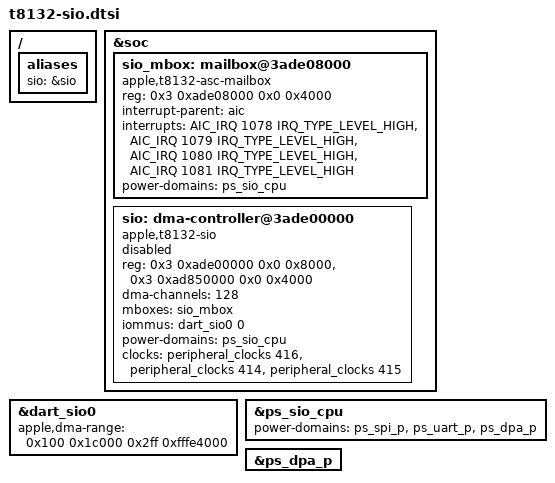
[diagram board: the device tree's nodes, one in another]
// SPDX-License-Identifier: GPL-2.0+ OR MIT
/*
 * T8132 SIO resources. iBoot preloads the SIO firmware; the boot loader
 * reserves it, publishes the boot tables (T6041 layout) and enables the SIO
 * node, which it finds by the alias. Without such a loader the SIO stays
 * disabled and nothing else changes.
 */

/ {
	aliases {
		sio = &sio;
	};
};

&soc {
	sio_mbox: mailbox@3ade08000 {
		compatible = "apple,t8132-asc-mailbox", "apple,asc-mailbox-v4";
		reg = <0x3 0xade08000 0x0 0x4000>;
		interrupt-parent = <&aic>;
		interrupts = <AIC_IRQ 1078 IRQ_TYPE_LEVEL_HIGH>,
		             <AIC_IRQ 1079 IRQ_TYPE_LEVEL_HIGH>,
		             <AIC_IRQ 1080 IRQ_TYPE_LEVEL_HIGH>,
		             <AIC_IRQ 1081 IRQ_TYPE_LEVEL_HIGH>;
		interrupt-names = "send-empty", "send-not-empty",
				  "recv-empty", "recv-not-empty";
		#mbox-cells = <0>;
		power-domains = <&ps_sio_cpu>;
		status = "okay";
	};

	sio: dma-controller@3ade00000 {
		compatible = "apple,t8132-sio", "apple,sio";
		reg = <0x3 0xade00000 0x0 0x8000>,
		      <0x3 0xad850000 0x0 0x4000>;
		reg-names = "asc", "auxiliary";
		#dma-cells = <1>;
		/* Channel numbers run up to dp-audio2's 0x68, as on T8140. */
		dma-channels = <128>;
		mboxes = <&sio_mbox>;
		iommus = <&dart_sio0 0>;
		power-domains = <&ps_sio_cpu>;
		clocks = <&peripheral_clocks 416>, <&peripheral_clocks 414>, <&peripheral_clocks 415>;
		status = "disabled";
	};
};

/* The boot tables sit in the window above the preloaded segments (ADT vm-base, vm-size). */
&dart_sio0 {
	apple,dma-range = <0x100 0x1c000 0x2ff 0xfffe4000>;
	status = "okay";
};

/*
 * The SIO firmware drives the SPI, UART and DP audio shims, so keep their
 * parents on while it runs, as on T6041 and T8140.
 */
&ps_sio_cpu {
	power-domains = <&ps_spi_p>, <&ps_uart_p>, <&ps_dpa_p>;
	status = "okay";
};

&ps_dpa_p {
	status = "okay";
};
